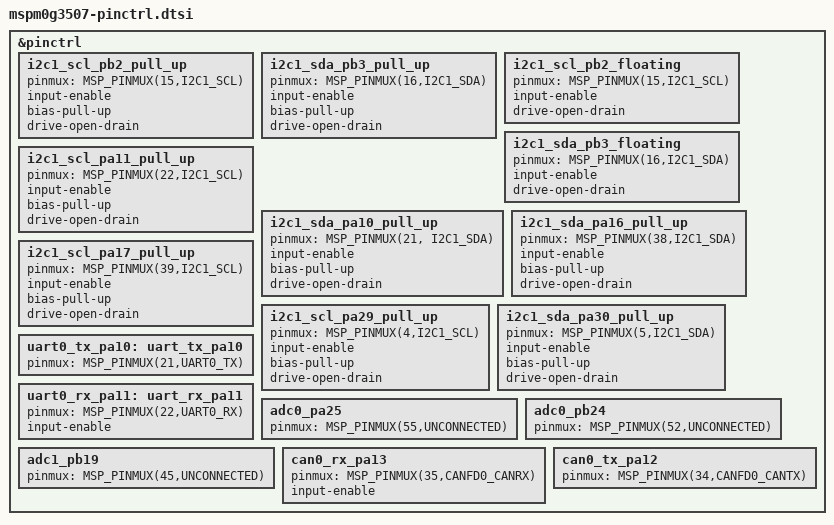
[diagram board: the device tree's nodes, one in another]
#include <dt-bindings/pinctrl/mspm0-pinctrl.h>

&pinctrl {

	i2c1_scl_pb2_pull_up: i2c1_scl_pb2_pull_up {
		pinmux = <MSP_PINMUX(15,I2C1_SCL)>;
		input-enable;
		bias-pull-up;
		drive-open-drain;
	};

	i2c1_sda_pb3_pull_up: i2c1_sda_pb3_pull_up {
		pinmux = <MSP_PINMUX(16,I2C1_SDA)>;
		input-enable;
		bias-pull-up;
		drive-open-drain;
	};

	i2c1_scl_pb2_floating: i2c1_scl_pb2_floating {
		pinmux = <MSP_PINMUX(15,I2C1_SCL)>;
		input-enable;
		drive-open-drain;
	};

	i2c1_sda_pb3_floating: i2c1_sda_pb3_floating {
		pinmux = <MSP_PINMUX(16,I2C1_SDA)>;
		input-enable;
		drive-open-drain;
	};

	i2c1_scl_pa11_pull_up: i2c1_scl_pa11_pull_up {
		pinmux = <MSP_PINMUX(22,I2C1_SCL)>;
		input-enable;
		bias-pull-up; 
		drive-open-drain;
	};

	i2c1_sda_pa10_pull_up: i2c1_sda_pa10_pull_up {
		pinmux = <MSP_PINMUX(21, I2C1_SDA)>;
		input-enable;
		bias-pull-up; 
		drive-open-drain;
	};

	i2c1_sda_pa16_pull_up: i2c1_sda_pa16_pull_up {
		pinmux = <MSP_PINMUX(38,I2C1_SDA)>;
		input-enable;
		bias-pull-up;
		drive-open-drain;
	};

	i2c1_scl_pa17_pull_up: i2c1_scl_pa17_pull_up {
		pinmux = <MSP_PINMUX(39,I2C1_SCL)>;
		input-enable;
		bias-pull-up;
		drive-open-drain;
	};

	i2c1_scl_pa29_pull_up: i2c1_scl_pa29_pull_up {
		pinmux = <MSP_PINMUX(4,I2C1_SCL)>;
		input-enable;
		bias-pull-up;
		drive-open-drain;
	};

	i2c1_sda_pa30_pull_up: i2c1_sda_pa30_pull_up {
		pinmux = <MSP_PINMUX(5,I2C1_SDA)>;
		input-enable;
		bias-pull-up;
		drive-open-drain;
	};

	uart0_tx_pa10: uart_tx_pa10 {
		pinmux = <MSP_PINMUX(21,UART0_TX)>;
	};

	uart0_rx_pa11: uart_rx_pa11 {
		pinmux = <MSP_PINMUX(22,UART0_RX)>;
		input-enable;
	};

	adc0_pa25: adc0_pa25 {
		pinmux = <MSP_PINMUX(55,UNCONNECTED)>;
	};

	adc0_pb24: adc0_pb24 {
		pinmux = <MSP_PINMUX(52,UNCONNECTED)>;
	};

	adc1_pb19: adc1_pb19 {
		pinmux = <MSP_PINMUX(45,UNCONNECTED)>;
	};

	can0_rx_pa13: can0_rx_pa13 {
		pinmux = <MSP_PINMUX(35,CANFD0_CANRX)>;
		input-enable;
	};

	can0_tx_pa12: can0_tx_pa12 {
		pinmux = <MSP_PINMUX(34,CANFD0_CANTX)>;
	};

};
